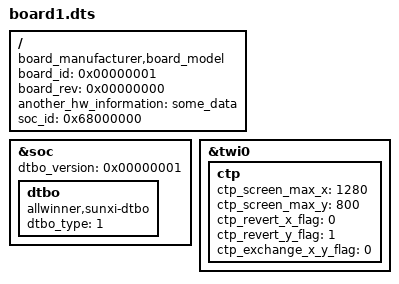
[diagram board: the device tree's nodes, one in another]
/dts-v1/;
/plugin/;
/ {
  /* As DTS design, these properties only for loader, won't overlay */
  compatible = "board_manufacturer,board_model";

  /* These properties are examples */
  board_id = <0x00000001>;
  board_rev = <0x00000000>;
  another_hw_information = "some_data";
  soc_id = <0x68000000>;

};

&soc {
	dtbo_version = <0x00000001>;
	dtbo{
		compatible = "allwinner,sunxi-dtbo";
		dtbo_type = <1>;
	};
};
&twi0 {
	ctp {
		ctp_screen_max_x = <1280>;
		ctp_screen_max_y = <800>;
		ctp_revert_x_flag = <0>;
		ctp_revert_y_flag = <1>;
		ctp_exchange_x_y_flag = <0>;
	};
};
